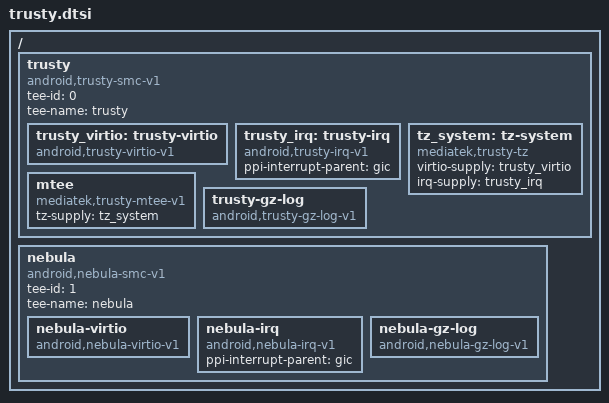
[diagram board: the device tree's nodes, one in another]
// SPDX-License-Identifier: GPL-2.0
/*
 * Copyright (c) 2019 MediaTek Inc.
 */

/ {
	trusty:trusty {
		compatible = "android,trusty-smc-v1";
		ranges;
		#address-cells = <2>;
		#size-cells = <2>;
		tee-id = <0>;
		tee-name = "trusty";

		trusty_virtio:trusty-virtio {
			compatible = "android,trusty-virtio-v1";
		};

		trusty_irq:trusty-irq {
			compatible = "android,trusty-irq-v1";
			ppi-interrupt-parent = <&gic>;
		};

		tz_system:tz-system {
			compatible = "mediatek,trusty-tz";
			virtio-supply = <&trusty_virtio>;
			irq-supply = <&trusty_irq>;
		};

		mtee {
			compatible = "mediatek,trusty-mtee-v1";
			tz-supply = <&tz_system>;
		};

		trusty-gz-log {
			compatible = "android,trusty-gz-log-v1";
		};
	};

	nebula {
		compatible = "android,nebula-smc-v1";
		ranges;
		#address-cells = <2>;
		#size-cells = <2>;
		tee-id = <1>;
		tee-name = "nebula";

		nebula-virtio {
			compatible = "android,nebula-virtio-v1";
		};

		nebula-irq {
			compatible = "android,nebula-irq-v1";
			ppi-interrupt-parent = <&gic>;
		};

		nebula-gz-log {
			compatible = "android,nebula-gz-log-v1";
		};
	};
};
